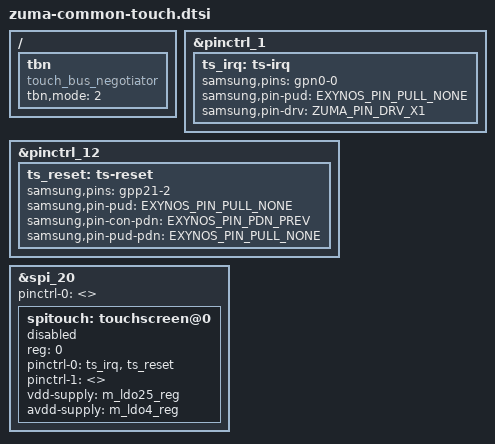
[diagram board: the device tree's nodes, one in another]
// SPDX-License-Identifier: GPL-2.0-only
/*
 * Google Zuma touch device tree source
 *
 * Copyright 2022 Google, LLC.
 */

/* Touch is connected to spi_20, pins:
 *   CLK=GPB10[4], MOSI=GPB10[5], MISO=GPB10[6], CS=GPB10[7]
 * TS1_RESET_L = XAPC_USI11_RTSn_DI = GPP21[2] = <&gpp21 2 0>
 * TS1_INT_L = AOC_APM_TS1_INT_L_R1 / XAOC_GPIO0 = GPN0[0] = <&gpn0 0 0>
 *
 * DVDD = PP1800_L25M_TS1_DVDD = VLDO25M
 * AVDD = PP3300_L4M_TS1_AVDD  = VLDO4M
 */

#include <dt-bindings/pinctrl/samsung.h>

/ {
	fragment@touch_bus_negotiator {
		target-path = "/";
		__overlay__ {
			tbn: tbn {
				compatible = "touch_bus_negotiator";
				tbn,mode = <2>;
			};
		};
	};
};

/* GPIO_CUSTOM_ALIVE */
&pinctrl_1 {
	ts_irq: ts-irq {
		samsung,pins = "gpn0-0";
		samsung,pin-pud = <EXYNOS_PIN_PULL_NONE>;
		samsung,pin-drv = <ZUMA_PIN_DRV_X1>;
	};
};

&pinctrl_12 {
	ts_reset: ts-reset {
		samsung,pins = "gpp21-2";
		samsung,pin-pud = <EXYNOS_PIN_PULL_NONE>;
		samsung,pin-con-pdn = <EXYNOS_PIN_PDN_PREV>;
		samsung,pin-pud-pdn = <EXYNOS_PIN_PULL_NONE>;
	};
};

/* TODO: pinctrl for ts_spi_bus_active, ts_spi_cs_active,
 * ts_spi_bus_sleep, ts_spi_miso_sleep, ts_spi_cs_sleep
 */

&spi_20 {
	#address-cells = <1>;
	#size-cells = <0>;
	status = "okay";
	pinctrl-0 = <>; /* TODO: pinctrl */

	spitouch: touchscreen@0 {
		#address-cells = <1>;
		#size-cells = <1>;

		status = "disabled";
		reg = <0>;
		pinctrl-names = "ts_active", "ts_suspend";
		pinctrl-0 = <&ts_irq &ts_reset>; /* TODO: pinctrl */
		pinctrl-1 = <>;

		vdd-supply = <&m_ldo25_reg>;
		avdd-supply = <&m_ldo4_reg>;
	};
};
